# STM32F446 register map
File version: 1.9
CPU: CM4 r0p1, little endian, MPU, FPU, 4 interrupt priority bits
Registers are 32-bit, read-write, reset 0x0 unless marked. A register's access mark holds for its fields unless they carry their own. Offsets are from the block's base; [hi:lo] are bit positions.

## OTG_HS_PWRCLK — USB on the go high speed
Base 0x40040E00
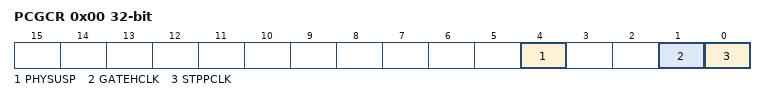
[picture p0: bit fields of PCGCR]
0x00 PCGCR — Power and clock gating control register
  [4] PHYSUSP — PHY suspended
  [1] GATEHCLK
  [0] STPPCLK — Stop PHY clock

## SPDIFRX — Receiver Interface
Base 0x40004000
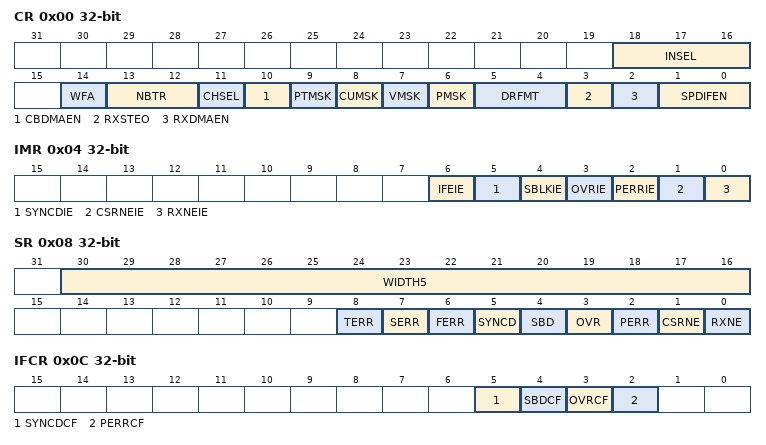
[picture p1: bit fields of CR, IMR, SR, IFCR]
0x00 CR — Control register
  [18:16] INSEL — input selection
  [14] WFA — Wait For Activity
  [13:12] NBTR — Maximum allowed re-tries during synchronization phase
  [11] CHSEL — Channel Selection
  [10] CBDMAEN — Control Buffer DMA ENable for control flow
  [9] PTMSK — Mask of Preamble Type bits
  [8] CUMSK — Mask of channel status and user bits
  [7] VMSK — Mask of Validity bit
  [6] PMSK — Mask Parity error bit
  [5:4] DRFMT — RX Data format
  [3] RXSTEO — STerEO Mode
  [2] RXDMAEN — Receiver DMA ENable for data flow
  [1:0] SPDIFEN — Peripheral Block Enable
0x04 IMR — Interrupt mask register
  [6] IFEIE — Serial Interface Error Interrupt Enable
  [5] SYNCDIE — Synchronization Done
  [4] SBLKIE — Synchronization Block Detected Interrupt Enable
  [3] OVRIE — Overrun error Interrupt Enable
  [2] PERRIE — Parity error interrupt enable
  [1] CSRNEIE — Control Buffer Ready Interrupt Enable
  [0] RXNEIE — RXNE interrupt enable
0x08 SR ro — Status register
  [30:16] WIDTH5 — Duration of 5 symbols counted with SPDIF_CLK
  [8] TERR — Time-out error
  [7] SERR — Synchronization error
  [6] FERR — Framing error
  [5] SYNCD — Synchronization Done
  [4] SBD — Synchronization Block Detected
  [3] OVR — Overrun error
  [2] PERR — Parity error
  [1] CSRNE — Control Buffer register is not empty
  [0] RXNE — Read data register not empty
0x0C IFCR wo — Interrupt Flag Clear register
  [5] SYNCDCF — Clears the Synchronization Done flag
  [4] SBDCF — Clears the Synchronization Block Detected flag
  [3] OVRCF — Clears the Overrun error flag
  [2] PERRCF — Clears the Parity error flag
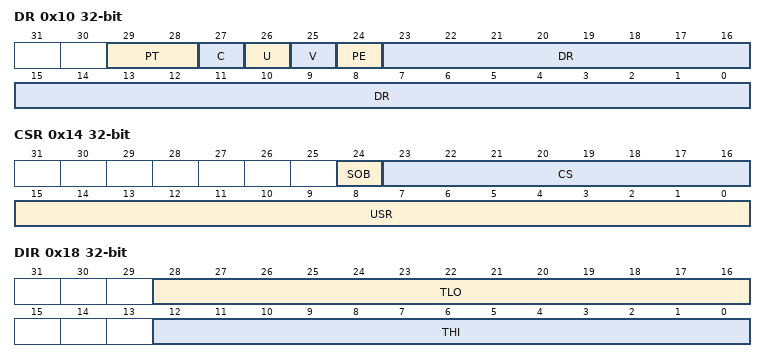
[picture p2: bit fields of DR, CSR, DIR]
0x10 DR ro — Data input register
  [29:28] PT — Preamble Type
  [27] C — Channel Status bit
  [26] U — User bit
  [25] V — Validity bit
  [24] PE — Parity Error bit
  [23:0] DR — Parity Error bit
0x14 CSR ro — Channel Status register
  [24] SOB — Start Of Block
  [23:16] CS — Channel A status information
  [15:0] USR — User data information
0x18 DIR ro — Debug Information register
  [28:16] TLO — Threshold LOW
  [12:0] THI — Threshold HIGH

## HDMI_CEC — HDMI-CEC controller
Base 0x40006C00
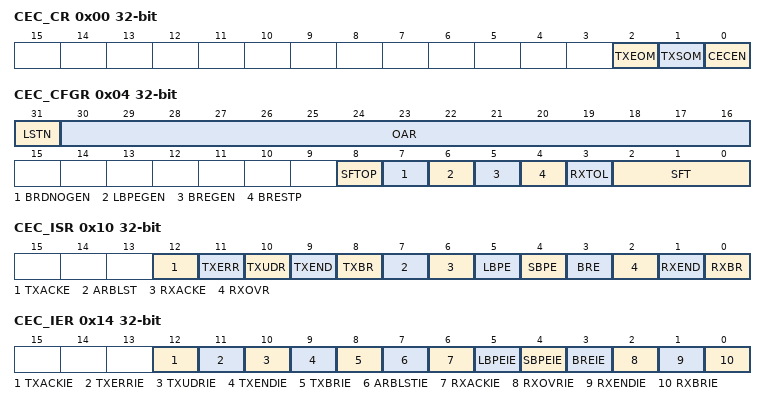
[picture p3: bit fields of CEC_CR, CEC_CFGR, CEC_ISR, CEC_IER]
0x00 CEC_CR access per field — CEC control register
  [2] TXEOM ro — Tx End Of Message
  [1] TXSOM ro — Tx Start Of Message
  [0] CECEN rw — CEC Enable
0x04 CEC_CFGR — CEC configuration register
  [31] LSTN — Listen mode
  [30:16] OAR — Own addresses configuration
  [8] SFTOP — SFT Option Bit
  [7] BRDNOGEN — Avoid Error-Bit Generation in Broadcast
  [6] LBPEGEN — Generate Error-Bit on Long Bit Period Error
  [5] BREGEN — Generate Error-Bit on Bit Rising Error
  [4] BRESTP — Rx-Stop on Bit Rising Error
  [3] RXTOL — Rx-Tolerance
  [2:0] SFT — Signal Free Time
0x08 CEC_TXDR wo — CEC Tx data register
  [7:0] TXD — Tx Data register
0x0C CEC_RXDR ro — CEC Rx Data Register
  [7:0] RXD — Rx Data register
0x10 CEC_ISR — CEC Interrupt and Status Register
  [12] TXACKE — Tx-Missing Acknowledge Error
  [11] TXERR — Tx-Error
  [10] TXUDR — Tx-Buffer Underrun
  [9] TXEND — End of Transmission
  [8] TXBR — Tx-Byte Request
  [7] ARBLST — Arbitration Lost
  [6] RXACKE — Rx-Missing Acknowledge
  [5] LBPE — Rx-Long Bit Period Error
  [4] SBPE — Rx-Short Bit Period Error
  [3] BRE — Rx-Bit Rising Error
  [2] RXOVR — Rx-Overrun
  [1] RXEND — End Of Reception
  [0] RXBR — Rx-Byte Received
0x14 CEC_IER — CEC interrupt enable register
  [12] TXACKIE — Tx-Missing Acknowledge Error Interrupt Enable
  [11] TXERRIE — Tx-Error Interrupt Enable
  [10] TXUDRIE — Tx-Underrun Interrupt Enable
  [9] TXENDIE — Tx-End Of Message Interrupt Enable
  [8] TXBRIE — Tx-Byte Request Interrupt Enable
  [7] ARBLSTIE — Arbitration Lost Interrupt Enable
  [6] RXACKIE — Rx-Missing Acknowledge Error Interrupt Enable
  [5] LBPEIE — Long Bit Period Error Interrupt Enable
  [4] SBPEIE — Short Bit Period Error Interrupt Enable
  [3] BREIE — Bit Rising Error Interrupt Enable
  [2] RXOVRIE — Rx-Buffer Overrun Interrupt Enable
  [1] RXENDIE — End Of Reception Interrupt Enable
  [0] RXBRIE — Rx-Byte Received Interrupt Enable
